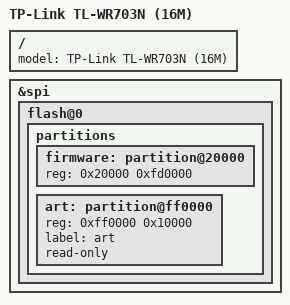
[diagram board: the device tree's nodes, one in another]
// SPDX-License-Identifier: GPL-2.0-or-later OR MIT
/dts-v1/;

#include "ar9331_tplink_tl-wr703n.dts"

/ {
	model = "TP-Link TL-WR703N (16M)";
};

&spi {
	flash@0 {
		partitions {
			firmware: partition@20000 {
				reg = <0x20000 0xfd0000>;
			};

			/delete-node/ partition@3f0000;
			art: partition@ff0000 {
				reg = <0xff0000 0x10000>;
				label = "art";
				read-only;
			};
		};
	};
};
